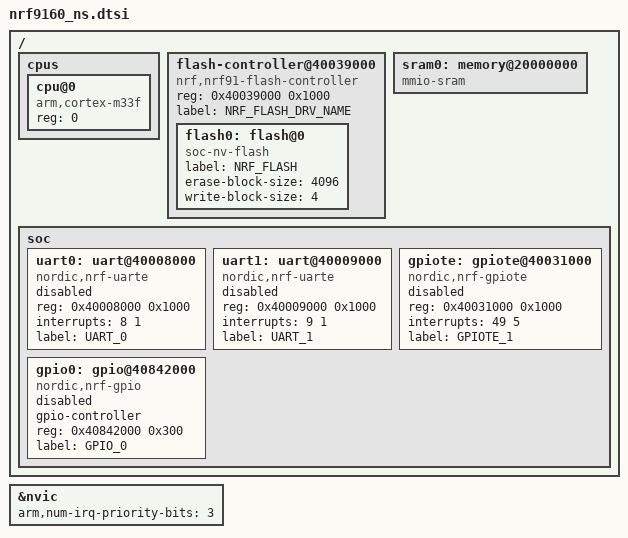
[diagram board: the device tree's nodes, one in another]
#include <arm/armv8-m.dtsi>
#include <dt-bindings/gpio/gpio.h>


/ {
	cpus {
		#address-cells = <1>;
		#size-cells = <0>;

		cpu@0 {
			device_type = "cpu";
			compatible = "arm,cortex-m33f";
			reg = <0>;
		};
	};

	flash-controller@40039000 {
			compatible = "nrf,nrf91-flash-controller";
			reg = <0x40039000 0x1000>;

			#address-cells = <1>;
			#size-cells = <1>;

			label="NRF_FLASH_DRV_NAME";

			flash0: flash@0 {
				compatible = "soc-nv-flash";
				label = "NRF_FLASH";
				erase-block-size = <4096>;
				write-block-size = <4>;
			};
	};

	sram0: memory@20000000 {
		device_type = "memory";
		compatible = "mmio-sram";
	};

	soc {
		uart0: uart@40008000 {
			compatible = "nordic,nrf-uarte";
			reg = <0x40008000 0x1000>;
			interrupts = <8 1>;
			status = "disabled";
			label = "UART_0";
		};

		uart1: uart@40009000 {
			compatible = "nordic,nrf-uarte";
			reg = <0x40009000 0x1000>;
			interrupts = <9 1>;
			status = "disabled";
			label = "UART_1";
		};

		gpiote: gpiote@40031000 {
			compatible = "nordic,nrf-gpiote";
			reg = <0x40031000 0x1000>;
			interrupts = <49 5>;
			interrupt-names = "gpiote";
			status = "disabled";
			label = "GPIOTE_1";
		};

		gpio0: gpio@40842000 {
			compatible = "nordic,nrf-gpio";
			gpio-controller;
			reg = <0x40842000 0x300>;
			#gpio-cells = <2>;
			label = "GPIO_0";
			status = "disabled";
		};

	};
};

&nvic {
	arm,num-irq-priority-bits = <3>;
};
